# STM32H725 register map
File version: 2.0
CPU: CM7 r0p1, little endian, MPU, FPU, 4 interrupt priority bits
Registers are 32-bit, read-write, reset 0x0 unless marked. A register's access mark holds for its fields unless they carry their own. Offsets are from the block's base; [hi:lo] are bit positions; {n}, {i} and the like mark numbered series.

## GPIOA — GPIO
Base 0x58020000
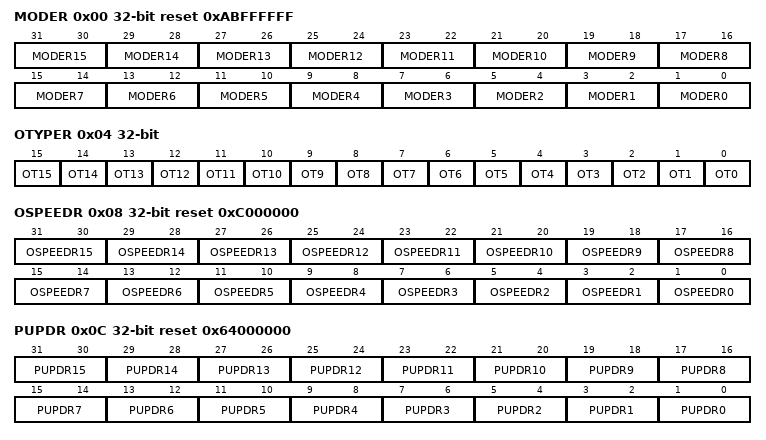
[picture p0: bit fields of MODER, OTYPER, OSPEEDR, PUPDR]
0x00 MODER reset 0xABFFFFFF — GPIO port mode register
  [2n+1:2n] MODER{n} (n=0..15) — Port x configuration pin {n}
    0=Input mode (reset state); 1=Output (General purpose output mode); 2=Alternate function mode; 3=Analog mode
0x04 OTYPER — GPIO port output type register
  [n] OT{n} (n=0..15) — Port x configuration pin {n}
    0=PushPull (Output push-pull (reset state)); 1=OpenDrain (Output open-drain)
0x08 OSPEEDR reset 0xC000000 — GPIO port output speed register
  [2n+1:2n] OSPEEDR{n} (n=0..15) — Port x configuration pin {n}
    0=LowSpeed; 1=MediumSpeed; 2=HighSpeed; 3=VeryHighSpeed
0x0C PUPDR reset 0x64000000 — GPIO port pull-up/pull-down register
  [2n+1:2n] PUPDR{n} (n=0..15) — Port x configuration pin {n}
    0=Floating (No pull-up, pull-down); 1=PullUp; 2=PullDown
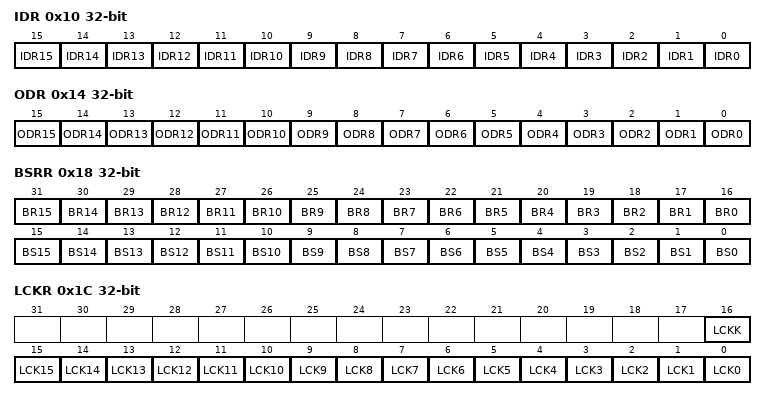
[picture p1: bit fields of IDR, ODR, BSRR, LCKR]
0x10 IDR ro — GPIO port input data register
  [n] IDR{n} (n=0..15) — Port input data pin {n}
    0=Low (Input is logic low); 1=High (Input is logic high)
0x14 ODR — GPIO port output data register
  [n] ODR{n} (n=0..15) — Port output data pin {n}
    0=Low (Set output to logic low); 1=High (Set output to logic high)
0x18 BSRR wo — GPIO port bit set/reset register
  [n+16] BR{n} (n=0..15) — Port x reset pin {n}
    1=Resets the corresponding ODRx bit
  [n] BS{n} (n=0..15) — Port x set pin {n}
    1=Set (Sets the corresponding ODRx bit)
0x1C LCKR — This register is used to lock the configuration of the port bits when a correct write sequence is applied to bit 16 (LCKK). The value of bits [15:0] is used to lock the configuration of the GPIO. During the write sequence, the value of LCKR[15:0] must not change. When the LOCK sequence has been applied on a port bit, the value of this port bit can no longer be modified until the next MCU reset or peripheral reset.A specific write sequence is used to write to the GPIOx_LCKR register. Only word access (32-bit long) is allowed during this locking sequence.Each lock bit freezes a specific configuration register (control and alternate function registers).
  [16] LCKK — Lock key This bit can be read any time. It can only be modified using the lock key write sequence. LOCK key write sequence: WR LCKR[16] = 1 + LCKR[15:0] WR LCKR[16] = 0 + LCKR[15:0] WR LCKR[16] = 1 + LCKR[15:0] RD LCKR RD LCKR[16] = 1 (this read operation is optional but it confirms that the lock is active) Note: During the LOCK key write sequence, the value of LCK[15:0] must not change. Any error in the lock sequence aborts the lock. After the first lock sequence on any bit of the port, any read access on the LCKK bit will return 1 until the next MCU reset or peripheral reset.
    0=NotActive (Port configuration lock key not active); 1=Active (Port configuration lock key active)
  [n] LCK{n} (n=0..15) — Port x lock pin {n}
    0=Unlocked (Port configuration not locked); 1=Locked (Port configuration locked)
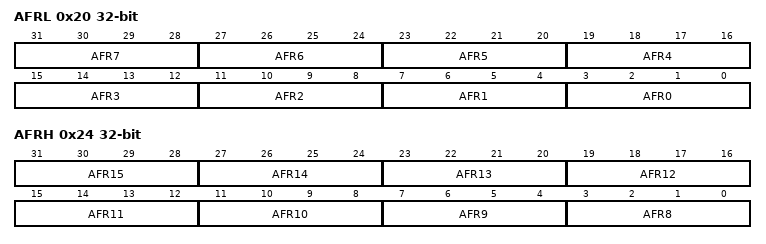
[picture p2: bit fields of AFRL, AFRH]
0x20 AFRL — GPIO alternate function low register
  [4n+3:4n] AFR{n} (n=0..7) — [3:0]: Alternate function selection for port x pin y (y = 0..7) These bits are written by software to configure alternate function I/Os AFSELy selection:
    {v}=AF{v} (v=0..15)
0x24 AFRH — GPIO alternate function high register
  [4n-29:4n-32] AFR{n} (n=8..15) — [3:0]: Alternate function selection for port x pin y (y = 8..15) These bits are written by software to configure alternate function I/Os
    {v}=AF{v} (v=0..15)

## GPIOC — GPIO
Base 0x58020800
Same registers: GPIOD 0x58020C00, GPIOE 0x58021000, GPIOF 0x58021400, GPIOG 0x58021800, GPIOH 0x58021C00
Registers as GPIOA; these are added or differ:
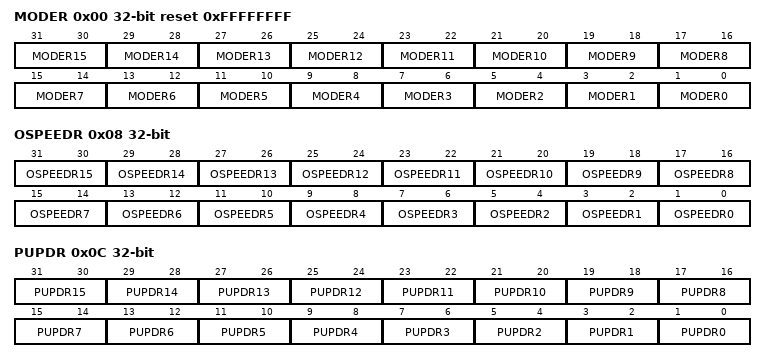
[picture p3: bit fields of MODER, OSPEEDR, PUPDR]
0x00 MODER reset 0xFFFFFFFF — GPIO port mode register
  [2n+1:2n] MODER{n} (n=0..15) — Port x configuration pin {n}
    0=Input mode (reset state); 1=Output (General purpose output mode); 2=Alternate function mode; 3=Analog mode
0x08 OSPEEDR — GPIO port output speed register
  [2n+1:2n] OSPEEDR{n} (n=0..15) — Port x configuration pin {n}
    0=LowSpeed; 1=MediumSpeed; 2=HighSpeed; 3=VeryHighSpeed
0x0C PUPDR — GPIO port pull-up/pull-down register
  [2n+1:2n] PUPDR{n} (n=0..15) — Port x configuration pin {n}
    0=Floating (No pull-up, pull-down); 1=PullUp; 2=PullDown

## GPIOJ — GPIO
Base 0x58022400
Registers as GPIOC; these are added or differ:
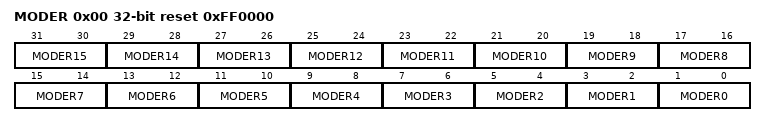
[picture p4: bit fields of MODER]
0x00 MODER reset 0xFF0000 — GPIO port mode register
  [2n+1:2n] MODER{n} (n=0..15) — Port x configuration pin {n}
    0=Input mode (reset state); 1=Output (General purpose output mode); 2=Alternate function mode; 3=Analog mode

## GPIOK — GPIO
Base 0x58022800
Registers as GPIOC; these are added or differ:
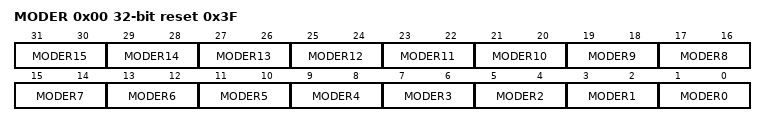
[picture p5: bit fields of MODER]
0x00 MODER reset 0x3F — GPIO port mode register
  [2n+1:2n] MODER{n} (n=0..15) — Port x configuration pin {n}
    0=Input mode (reset state); 1=Output (General purpose output mode); 2=Alternate function mode; 3=Analog mode

## GPIOB — GPIO
Base 0x58020400
Registers as GPIOA; these are added or differ:
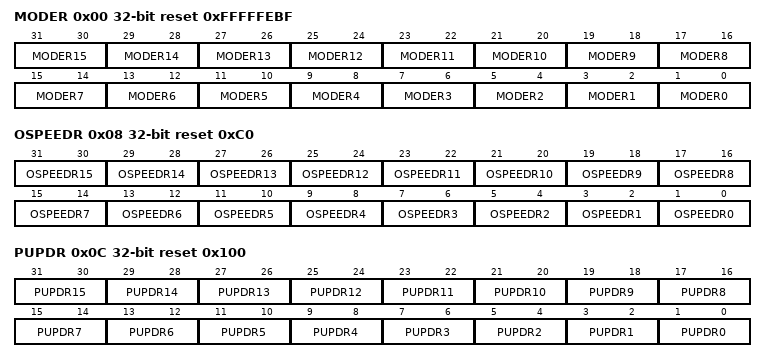
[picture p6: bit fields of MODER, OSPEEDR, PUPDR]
0x00 MODER reset 0xFFFFFEBF — GPIO port mode register
  [2n+1:2n] MODER{n} (n=0..15) — Port x configuration pin {n}
    0=Input mode (reset state); 1=Output (General purpose output mode); 2=Alternate function mode; 3=Analog mode
0x08 OSPEEDR reset 0xC0 — GPIO port output speed register
  [2n+1:2n] OSPEEDR{n} (n=0..15) — Port x configuration pin {n}
    0=LowSpeed; 1=MediumSpeed; 2=HighSpeed; 3=VeryHighSpeed
0x0C PUPDR reset 0x100 — GPIO port pull-up/pull-down register
  [2n+1:2n] PUPDR{n} (n=0..15) — Port x configuration pin {n}
    0=Floating (No pull-up, pull-down); 1=PullUp; 2=PullDown
